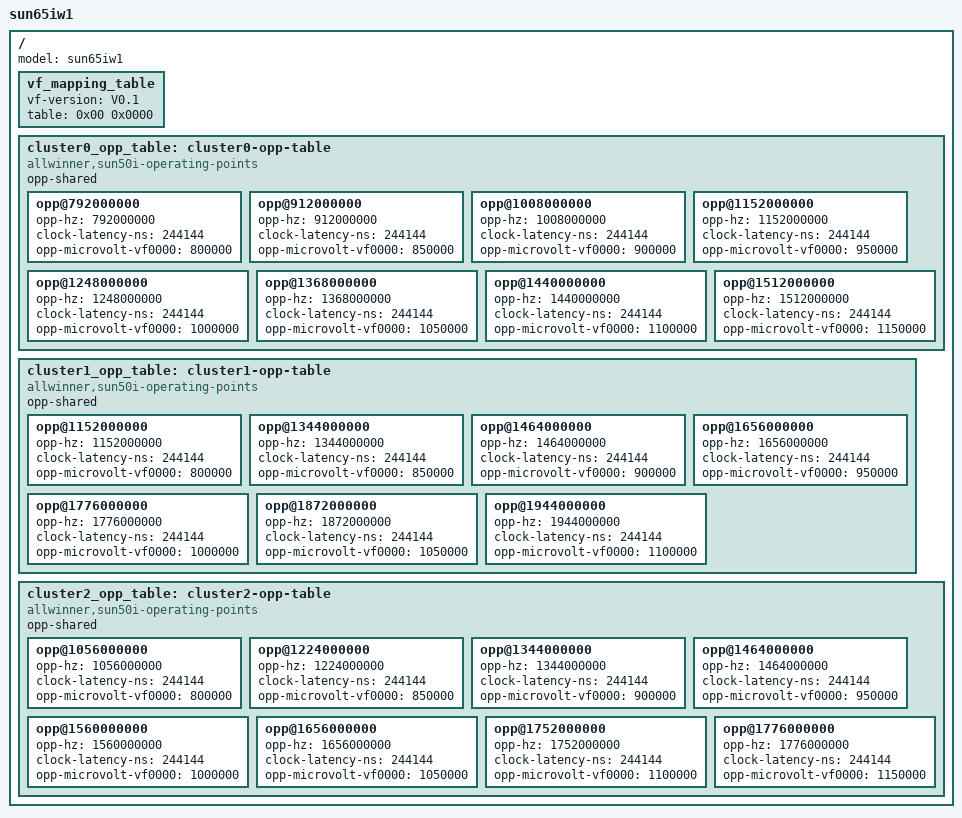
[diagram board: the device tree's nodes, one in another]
/* SPDX-License-Identifier: GPL-2.0-or-later */
/{
	model = "sun65iw1";

	vf_mapping_table: vf_mapping_table {
		vf-version = "V0.1";
		table = <
			0x00 0x0000
			>;
	};

	cluster0_opp_table: cluster0-opp-table {
		compatible = "allwinner,sun50i-operating-points";
		opp-shared;

		opp@792000000 {
			opp-hz = /bits/ 64 <792000000>;
			clock-latency-ns = <244144>; /* 8 32k periods */
			opp-microvolt-vf0000 = <800000>;
		};

		opp@912000000 {
			opp-hz = /bits/ 64 <912000000>;
			clock-latency-ns = <244144>; /* 8 32k periods */
			opp-microvolt-vf0000 = <850000>;
		};

		opp@1008000000 {
			opp-hz = /bits/ 64 <1008000000>;
			clock-latency-ns = <244144>; /* 8 32k periods */
			opp-microvolt-vf0000 = <900000>;
		};

		opp@1152000000 {
			opp-hz = /bits/ 64 <1152000000>;
			clock-latency-ns = <244144>; /* 8 32k periods */
			opp-microvolt-vf0000 = <950000>;
		};

		opp@1248000000 {
			opp-hz = /bits/ 64 <1248000000>;
			clock-latency-ns = <244144>; /* 8 32k periods */
			opp-microvolt-vf0000 = <1000000>;
		};

		opp@1368000000 {
			opp-hz = /bits/ 64 <1368000000>;
			clock-latency-ns = <244144>; /* 8 32k periods */
			opp-microvolt-vf0000 = <1050000>;
		};

		opp@1440000000 {
			opp-hz = /bits/ 64 <1440000000>;
			clock-latency-ns = <244144>; /* 8 32k periods */
			opp-microvolt-vf0000 = <1100000>;
		};

		opp@1512000000 {
			opp-hz = /bits/ 64 <1512000000>;
			clock-latency-ns = <244144>; /* 8 32k periods */
			opp-microvolt-vf0000 = <1150000>;
		};
	};

	cluster1_opp_table: cluster1-opp-table {
		compatible = "allwinner,sun50i-operating-points";
		opp-shared;

		opp@1152000000 {
			opp-hz = /bits/ 64 <1152000000>;
			clock-latency-ns = <244144>; /* 8 32k periods */
			opp-microvolt-vf0000 = <800000>;
		};

		opp@1344000000 {
			opp-hz = /bits/ 64 <1344000000>;
			clock-latency-ns = <244144>; /* 8 32k periods */
			opp-microvolt-vf0000 = <850000>;
		};

		opp@1464000000 {
			opp-hz = /bits/ 64 <1464000000>;
			clock-latency-ns = <244144>; /* 8 32k periods */
			opp-microvolt-vf0000 = <900000>;
		};

		opp@1656000000 {
			opp-hz = /bits/ 64 <1656000000>;
			clock-latency-ns = <244144>; /* 8 32k periods */
			opp-microvolt-vf0000 = <950000>;
		};

		opp@1776000000 {
			opp-hz = /bits/ 64 <1776000000>;
			clock-latency-ns = <244144>; /* 8 32k periods */
			opp-microvolt-vf0000 = <1000000>;
		};

		opp@1872000000 {
			opp-hz = /bits/ 64 <1872000000>;
			clock-latency-ns = <244144>; /* 8 32k periods */
			opp-microvolt-vf0000 = <1050000>;
		};

		opp@1944000000 {
			opp-hz = /bits/ 64 <1944000000>;
			clock-latency-ns = <244144>; /* 8 32k periods */
			opp-microvolt-vf0000 = <1100000>;
		};
	};

	cluster2_opp_table: cluster2-opp-table {
		compatible = "allwinner,sun50i-operating-points";
		opp-shared;

		opp@1056000000 {
			opp-hz = /bits/ 64 <1056000000>;
			clock-latency-ns = <244144>; /* 8 32k periods */
			opp-microvolt-vf0000 = <800000>;
		};

		/* this freq support in 24m and 26m */
		opp@1224000000 {
			opp-hz = /bits/ 64 <1224000000>;
			clock-latency-ns = <244144>; /* 8 32k periods */
			opp-microvolt-vf0000 = <850000>;
		};

		opp@1344000000 {
			opp-hz = /bits/ 64 <1344000000>;
			clock-latency-ns = <244144>; /* 8 32k periods */
			opp-microvolt-vf0000 = <900000>;
		};

		opp@1464000000 {
			opp-hz = /bits/ 64 <1464000000>;
			clock-latency-ns = <244144>; /* 8 32k periods */
			opp-microvolt-vf0000 = <950000>;
		};

		opp@1560000000 {
			opp-hz = /bits/ 64 <1560000000>;
			clock-latency-ns = <244144>; /* 8 32k periods */
			opp-microvolt-vf0000 = <1000000>;
		};

		opp@1656000000 {
			opp-hz = /bits/ 64 <1656000000>;
			clock-latency-ns = <244144>; /* 8 32k periods */
			opp-microvolt-vf0000 = <1050000>;
		};

		opp@1752000000 {
			opp-hz = /bits/ 64 <1752000000>;
			clock-latency-ns = <244144>; /* 8 32k periods */
			opp-microvolt-vf0000 = <1100000>;
		};

		opp@1776000000 {
			opp-hz = /bits/ 64 <1776000000>;
			clock-latency-ns = <244144>; /* 8 32k periods */
			opp-microvolt-vf0000 = <1150000>;
		};
	};
};
